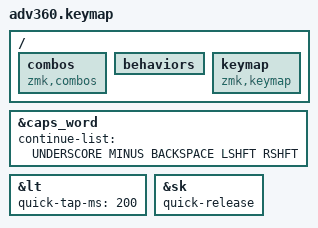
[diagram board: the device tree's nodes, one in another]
#include <behaviors.dtsi>
#include <dt-bindings/zmk/keys.h>
#include <dt-bindings/zmk/bt.h>
#include <dt-bindings/zmk/rgb.h>
#include <dt-bindings/zmk/backlight.h>
#include "layers.dtsi"

&caps_word {
    continue-list = <UNDERSCORE MINUS BACKSPACE LSHFT RSHFT>;
    /delete-property/ ignore-modifiers;
};

&lt {
    quick-tap-ms = <200>;
};

&sk {
    quick-release;
};

/ {
    combos {
        compatible = "zmk,combos";
        #include "combos.dtsi"
    };
    behaviors {
        #include "macros.dtsi"
        #include "behaviors.dtsi"
    };
    keymap {
        compatible = "zmk,keymap";
        #include "keymap.dtsi"
    };
};
